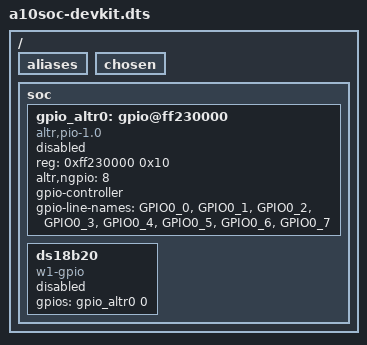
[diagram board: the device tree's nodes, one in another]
/*
 * TODO
 */

/dts-v1/;
#include "socfpga_arria10_socdk_sdmmc.dts"
#include <dt-bindings/gpio/gpio.h>

/ {
	aliases {
	};

	chosen {
	};

/*
 * Add GPIO configuration for Altera PIO IP.
 * Adjust Avalon MM address if needed.
 */
	soc {
		gpio_altr0: gpio@ff230000 {
			compatible = "altr,pio-1.0";
			reg = <0xff230000 0x10>;
			altr,ngpio = <8>;
			#gpio-cells = <2>;
			gpio-controller;
			gpio-line-names = "GPIO0_0","GPIO0_1","GPIO0_2","GPIO0_3","GPIO0_4","GPIO0_5","GPIO0_6","GPIO0_7";
			status = "disabled";
		};
	};

/*
 * 1-Wire temperature sensor (DS18B20)
 */
	soc {
		ds18b20 {
			compatible = "w1-gpio";
			gpios = <&gpio_altr0 0 (GPIO_ACTIVE_HIGH | GPIO_PULL_UP)>;
			status = "disabled";
		};
	};

};
